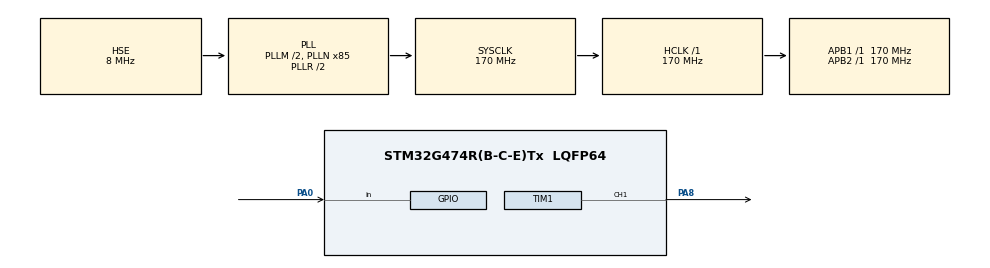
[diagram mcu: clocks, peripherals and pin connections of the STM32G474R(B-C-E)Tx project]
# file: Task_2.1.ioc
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Dma.Request0=TIM1_CH1
Dma.TIM1_CH1.0.Direction=DMA_MEMORY_TO_PERIPH
Dma.TIM1_CH1.0.EventEnable=DISABLE
Dma.TIM1_CH1.0.Instance=DMA1_Channel1
Dma.TIM1_CH1.0.MemDataAlignment=DMA_MDATAALIGN_HALFWORD
Dma.TIM1_CH1.0.MemInc=DMA_MINC_ENABLE
Dma.TIM1_CH1.0.Mode=DMA_NORMAL
Dma.TIM1_CH1.0.PeriphDataAlignment=DMA_PDATAALIGN_HALFWORD
Dma.TIM1_CH1.0.PeriphInc=DMA_PINC_DISABLE
Dma.TIM1_CH1.0.Polarity=HAL_DMAMUX_REQ_GEN_RISING
Dma.TIM1_CH1.0.Priority=DMA_PRIORITY_LOW
Dma.TIM1_CH1.0.RequestNumber=1
Dma.TIM1_CH1.0.SignalID=NONE
Dma.TIM1_CH1.0.SyncEnable=DISABLE
Dma.TIM1_CH1.0.SyncPolarity=HAL_DMAMUX_SYNC_NO_EVENT
Dma.TIM1_CH1.0.SyncRequestNumber=1
Dma.TIM1_CH1.0.SyncSignalID=NONE
Mcu.Family=STM32G4
Mcu.Name=STM32G474R(B-C-E)Tx
Mcu.Package=LQFP64
NVIC.DMA1_Channel1_IRQn=true\:0\:0\:false\:false\:true\:false\:true\:true
NVIC.PriorityGroup=NVIC_PRIORITYGROUP_4
PA0.GPIO_PuPd=GPIO_PULLDOWN
PA0.Signal=GPIO_Input
PA13.Mode=Serial_Wire
PA13.Signal=SYS_JTMS-SWDIO
PA14.Mode=Serial_Wire
PA14.Signal=SYS_JTCK-SWCLK
PA8.GPIO_Speed=GPIO_SPEED_FREQ_VERY_HIGH
PA8.Signal=S_TIM1_CH1
PF0-OSC_IN.Mode=HSE-External-Oscillator
PF0-OSC_IN.Signal=RCC_OSC_IN
PF1-OSC_OUT.Mode=HSE-External-Oscillator
PF1-OSC_OUT.Signal=RCC_OSC_OUT
ProjectManager.HeapSize=0x200
ProjectManager.StackSize=0x400
ProjectManager.TargetToolchain=EWARM V8.50
RCC.ADC12Freq_Value=170000000
RCC.ADC345Freq_Value=170000000
RCC.AHBFreq_Value=170000000
RCC.APB1Freq_Value=170000000
RCC.APB1TimFreq_Value=170000000
RCC.APB2Freq_Value=170000000
RCC.APB2TimFreq_Value=170000000
RCC.CortexFreq_Value=170000000
RCC.EXTERNAL_CLOCK_VALUE=12288000
RCC.HCLKFreq_Value=170000000
RCC.HSE_VALUE=8000000
RCC.HSI48_VALUE=48000000
RCC.HSI_VALUE=16000000
RCC.LSE_VALUE=32768
RCC.PLLM=RCC_PLLM_DIV2
RCC.PLLN=85
RCC.PLLSourceVirtual=RCC_PLLSOURCE_HSE
RCC.SYSCLKFreq_VALUE=170000000
RCC.SYSCLKSource=RCC_SYSCLKSOURCE_PLLCLK
RCC.USBFreq_Value=170000000
RCC.VCOOutputFreq_Value=340000000
SH.S_TIM1_CH1.0=TIM1_CH1,PWM Generation1 CH1
TIM1.Channel-PWM\ Generation1\ CH1=TIM_CHANNEL_1
TIM1.PeriodNoDither=211
VP_SYS_VS_DBSignals.Mode=DisableDeadBatterySignals
board=custom

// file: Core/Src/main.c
/* USER CODE BEGIN Header */
/**
  ******************************************************************************
  * @file           : main.c
  * @brief          : Main program body
  ******************************************************************************
  * @attention
  *
  * Copyright (c) 2026 STMicroelectronics.
  * All rights reserved.
  *
  * This software is licensed under terms that can be found in the LICENSE file
  * in the root directory of this software component.
  * If no LICENSE file comes with this software, it is provided AS-IS.
  *
  ******************************************************************************
  */
/* USER CODE END Header */
#include "main.h"

TIM_HandleTypeDef htim1;
DMA_HandleTypeDef hdma_tim1_ch1;

/* USER CODE BEGIN PV */
//
//
//
//
//
//
//
//
//
//
#define T_MS           3000   // color-change period
#define FRAME_MS       10     // update rate
#define BRIGHT_MAX     255    // lower (e.g. 64) if too bright
#define BLINK_HALF_MS  200    // 200 ms on, 200 ms off
#define BIT_0          70     // CCR for a 0 bit (~0.41 us)
#define BIT_1          140    // CCR for a 1 bit (~0.82 us)
#define LED_BITS       24
#define TAIL_SLOTS     2      // zeros at end keep the line low

static uint16_t pwm_buf[LED_BITS + TAIL_SLOTS];   // tail stays 0
static volatile uint8_t dma_busy = 0;
static uint8_t blinking = 0;
static uint32_t blink_start = 0;
//
//
//
//
//
//
//
//
//
//
/* USER CODE END PV */

void SystemClock_Config(void);
static void MX_GPIO_Init(void);
static void MX_DMA_Init(void);
static void MX_TIM1_Init(void);

/* USER CODE BEGIN 0 */
//
//
//
//
//
//
//
//
//
//
static void send_led(uint8_t r, uint8_t g, uint8_t b)
{
    if (dma_busy) return;                       // previous frame still going

    uint32_t color = ((uint32_t)g << 16) | ((uint32_t)r << 8) | b;  // GRB order
    for (int i = 0; i < LED_BITS; i++) {
        pwm_buf[i] = (color & (1UL << (23 - i))) ? BIT_1 : BIT_0;   // MSB first
    }

    dma_busy = 1;
    HAL_TIM_PWM_Start_DMA(&htim1, TIM_CHANNEL_1,
                          (uint32_t *)pwm_buf, LED_BITS + TAIL_SLOTS);
}

void HAL_TIM_PWM_PulseFinishedCallback(TIM_HandleTypeDef *htim)
{
    if (htim->Instance == TIM1) {
        HAL_TIM_PWM_Stop_DMA(htim, TIM_CHANNEL_1);
        dma_busy = 0;
    }
}
//
//
//
//
//
//
//
//
//
//
/* USER CODE END 0 */

int main(void)
{

  /* MCU Configuration--------------------------------------------------------*/

  /* Reset of all peripherals, Initializes the Flash interface and the Systick. */
  HAL_Init();

  /* Configure the system clock */
  SystemClock_Config();

  /* Initialize all configured peripherals */
  MX_GPIO_Init();
  MX_DMA_Init();
  MX_TIM1_Init();
  /* USER CODE BEGIN 2 */
  //
  //
  //
  //
  //
  //
  //
  //
  //
  //
  uint32_t next_frame = HAL_GetTick();
  uint8_t  prev_pressed = 0;
  //
  //
  //
  //
  //
  //
  //
  //
  //
  //
  /* USER CODE END 2 */

  /* Infinite loop */
  while (1)
  {

    /* USER CODE BEGIN 3 */
	  //
	  //
	  //
	  //
	  //
	  //
	  //
	  //
	  //
	  //
	  uint32_t now = HAL_GetTick();

	      if ((int32_t)(now - next_frame) >= 0)
	      {
	          next_frame += FRAME_MS;

	          uint32_t phase = now % T_MS;                       // 0 .. 2999 ms

	          // R: square wave, 50% duty
	          uint8_t r = (phase < T_MS / 2) ? BRIGHT_MAX : 0;

	          // G: sawtooth, ramps 0 -> max, then resets
	          uint8_t g = (phase * BRIGHT_MAX) / T_MS;

	          // B: 3 blinks after a button press
	          uint8_t pressed = (HAL_GPIO_ReadPin(BTN_GPIO_Port, BTN_Pin) == GPIO_PIN_RESET);
	          if (pressed && !prev_pressed && !blinking) {       // new press only
	              blinking = 1;
	              blink_start = now;
	          }
	          prev_pressed = pressed;

	          uint8_t b = 0;
	          if (blinking) {
	              uint32_t e = now - blink_start;
	              if (e >= 6 * BLINK_HALF_MS) {
	                  blinking = 0;                              // 3 on/off cycles done
	              } else {
	                  b = ((e / BLINK_HALF_MS) % 2 == 0) ? BRIGHT_MAX : 0;
	              }
	          }

	          send_led(r, g, b);
	      }
  }
  //
  //
  //
  //
  //
  //
  //
  //
  //
  //
  /* USER CODE END 3 */
}

void SystemClock_Config(void)
{
  RCC_OscInitTypeDef RCC_OscInitStruct = {0};
  RCC_ClkInitTypeDef RCC_ClkInitStruct = {0};

  /** Configure the main internal regulator output voltage
  */
  HAL_PWREx_ControlVoltageScaling(PWR_REGULATOR_VOLTAGE_SCALE1_BOOST);

  /** Initializes the RCC Oscillators according to the specified parameters
  * in the RCC_OscInitTypeDef structure.
  */
  RCC_OscInitStruct.OscillatorType = RCC_OSCILLATORTYPE_HSE;
  RCC_OscInitStruct.HSEState = RCC_HSE_ON;
  RCC_OscInitStruct.PLL.PLLState = RCC_PLL_ON;
  RCC_OscInitStruct.PLL.PLLSource = RCC_PLLSOURCE_HSE;
  RCC_OscInitStruct.PLL.PLLM = RCC_PLLM_DIV2;
  RCC_OscInitStruct.PLL.PLLN = 85;
  RCC_OscInitStruct.PLL.PLLP = RCC_PLLP_DIV2;
  RCC_OscInitStruct.PLL.PLLQ = RCC_PLLQ_DIV2;
  RCC_OscInitStruct.PLL.PLLR = RCC_PLLR_DIV2;
  if (HAL_RCC_OscConfig(&RCC_OscInitStruct) != HAL_OK)
  {
    Error_Handler();
  }

  /** Initializes the CPU, AHB and APB buses clocks
  */
  RCC_ClkInitStruct.ClockType = RCC_CLOCKTYPE_HCLK|RCC_CLOCKTYPE_SYSCLK
                              |RCC_CLOCKTYPE_PCLK1|RCC_CLOCKTYPE_PCLK2;
  RCC_ClkInitStruct.SYSCLKSource = RCC_SYSCLKSOURCE_PLLCLK;
  RCC_ClkInitStruct.AHBCLKDivider = RCC_SYSCLK_DIV1;
  RCC_ClkInitStruct.APB1CLKDivider = RCC_HCLK_DIV1;
  RCC_ClkInitStruct.APB2CLKDivider = RCC_HCLK_DIV1;

  if (HAL_RCC_ClockConfig(&RCC_ClkInitStruct, FLASH_LATENCY_4) != HAL_OK)
  {
    Error_Handler();
  }
}

static void MX_TIM1_Init(void)
{

  TIM_MasterConfigTypeDef sMasterConfig = {0};
  TIM_OC_InitTypeDef sConfigOC = {0};
  TIM_BreakDeadTimeConfigTypeDef sBreakDeadTimeConfig = {0};

  htim1.Instance = TIM1;
  htim1.Init.Prescaler = 0;
  htim1.Init.CounterMode = TIM_COUNTERMODE_UP;
  htim1.Init.Period = 211;
  htim1.Init.ClockDivision = TIM_CLOCKDIVISION_DIV1;
  htim1.Init.RepetitionCounter = 0;
  htim1.Init.AutoReloadPreload = TIM_AUTORELOAD_PRELOAD_DISABLE;
  if (HAL_TIM_PWM_Init(&htim1) != HAL_OK)
  {
    Error_Handler();
  }
  sMasterConfig.MasterOutputTrigger = TIM_TRGO_RESET;
  sMasterConfig.MasterOutputTrigger2 = TIM_TRGO2_RESET;
  sMasterConfig.MasterSlaveMode = TIM_MASTERSLAVEMODE_DISABLE;
  if (HAL_TIMEx_MasterConfigSynchronization(&htim1, &sMasterConfig) != HAL_OK)
  {
    Error_Handler();
  }
  sConfigOC.OCMode = TIM_OCMODE_PWM1;
  sConfigOC.Pulse = 0;
  sConfigOC.OCPolarity = TIM_OCPOLARITY_HIGH;
  sConfigOC.OCNPolarity = TIM_OCNPOLARITY_HIGH;
  sConfigOC.OCFastMode = TIM_OCFAST_DISABLE;
  sConfigOC.OCIdleState = TIM_OCIDLESTATE_RESET;
  sConfigOC.OCNIdleState = TIM_OCNIDLESTATE_RESET;
  if (HAL_TIM_PWM_ConfigChannel(&htim1, &sConfigOC, TIM_CHANNEL_1) != HAL_OK)
  {
    Error_Handler();
  }
  sBreakDeadTimeConfig.OffStateRunMode = TIM_OSSR_DISABLE;
  sBreakDeadTimeConfig.OffStateIDLEMode = TIM_OSSI_DISABLE;
  sBreakDeadTimeConfig.LockLevel = TIM_LOCKLEVEL_OFF;
  sBreakDeadTimeConfig.DeadTime = 0;
  sBreakDeadTimeConfig.BreakState = TIM_BREAK_DISABLE;
  sBreakDeadTimeConfig.BreakPolarity = TIM_BREAKPOLARITY_HIGH;
  sBreakDeadTimeConfig.BreakFilter = 0;
  sBreakDeadTimeConfig.BreakAFMode = TIM_BREAK_AFMODE_INPUT;
  sBreakDeadTimeConfig.Break2State = TIM_BREAK2_DISABLE;
  sBreakDeadTimeConfig.Break2Polarity = TIM_BREAK2POLARITY_HIGH;
  sBreakDeadTimeConfig.Break2Filter = 0;
  sBreakDeadTimeConfig.Break2AFMode = TIM_BREAK_AFMODE_INPUT;
  sBreakDeadTimeConfig.AutomaticOutput = TIM_AUTOMATICOUTPUT_DISABLE;
  if (HAL_TIMEx_ConfigBreakDeadTime(&htim1, &sBreakDeadTimeConfig) != HAL_OK)
  {
    Error_Handler();
  }
  HAL_TIM_MspPostInit(&htim1);

}

static void MX_DMA_Init(void)
{

  /* DMA controller clock enable */
  __HAL_RCC_DMAMUX1_CLK_ENABLE();
  __HAL_RCC_DMA1_CLK_ENABLE();

  /* DMA interrupt init */
  /* DMA1_Channel1_IRQn interrupt configuration */
  HAL_NVIC_SetPriority(DMA1_Channel1_IRQn, 0, 0);
  HAL_NVIC_EnableIRQ(DMA1_Channel1_IRQn);

}

static void MX_GPIO_Init(void)
{
  GPIO_InitTypeDef GPIO_InitStruct = {0};

  /* GPIO Ports Clock Enable */
  __HAL_RCC_GPIOF_CLK_ENABLE();
  __HAL_RCC_GPIOA_CLK_ENABLE();

  /*Configure GPIO pin : PA0 */
  GPIO_InitStruct.Pin = GPIO_PIN_0;
  GPIO_InitStruct.Mode = GPIO_MODE_INPUT;
  GPIO_InitStruct.Pull = GPIO_PULLDOWN;
  HAL_GPIO_Init(GPIOA, &GPIO_InitStruct);

}

void Error_Handler(void)
{
  __disable_irq();
  while (1)
  {
  }
}
